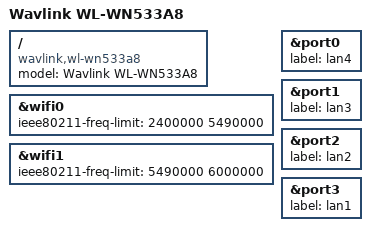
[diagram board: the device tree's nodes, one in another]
// SPDX-License-Identifier: GPL-2.0-or-later OR MIT

#include "mt7621_wavlink_wl-wn53xax.dtsi"

/ {
	compatible = "wavlink,wl-wn533a8", "mediatek,mt7621-soc";
	model = "Wavlink WL-WN533A8";
};

&wifi0{
	ieee80211-freq-limit = <2400000 5490000>;
};

&wifi1{
	ieee80211-freq-limit = <5490000 6000000>;
};

&port0{
	label = "lan4";
};

&port1{
	label = "lan3";
};

&port2{
	label = "lan2";
};

&port3{
	label = "lan1";
};
